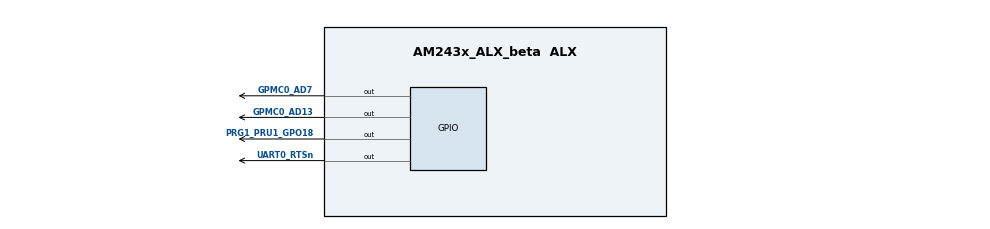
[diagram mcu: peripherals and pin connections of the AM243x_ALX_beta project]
/**
 * These arguments were used when this file was generated. They will be automatically applied on subsequent loads
 * via the GUI or CLI. Run CLI with '--help' for additional information on how to override these arguments.
 * @cliArgs --device "AM243x_ALX_beta" --package "ALX" --part "ALX" --context "r5fss0-0" --product "MCU_PLUS_SDK@07.03.01" --product "MCU_PLUS_IND_COMMS_LIBS@01.00.00.00"
 * @versions {"tool":"1.14.0+2667"}
 */

/**
 * Import the modules used in this configuration.
 */
const eeprom     = scripting.addModule("/board/eeprom/eeprom", {}, false);
const eeprom1    = eeprom.addInstance();
const flash      = scripting.addModule("/board/flash/flash", {}, false);
const flash1     = flash.addInstance();
const led        = scripting.addModule("/board/led/led", {}, false);
const led1       = led.addInstance();
const led2       = led.addInstance();
const led3       = led.addInstance();
const gpio       = scripting.addModule("/drivers/gpio/gpio", {}, false);
const gpio1      = gpio.addInstance();
const gpio2      = gpio.addInstance();
const gpio3      = gpio.addInstance();
const gpio4      = gpio.addInstance();
const i2c        = scripting.addModule("/drivers/i2c/i2c", {}, false);
const i2c1       = i2c.addInstance();
const pruicss    = scripting.addModule("/drivers/pruicss/pruicss", {}, false);
const pruicss1   = pruicss.addInstance();
const uart       = scripting.addModule("/drivers/uart/uart", {}, false);
const uart1      = uart.addInstance();
const ethercat   = scripting.addModule("/industrial_comms/ethercat/ethercat", {}, false);
const ethercat1  = ethercat.addInstance();
const clock      = scripting.addModule("/kernel/dpl/clock");
const debug_log  = scripting.addModule("/kernel/dpl/debug_log");
const mpu_armv7  = scripting.addModule("/kernel/dpl/mpu_armv7", {}, false);
const mpu_armv71 = mpu_armv7.addInstance();
const mpu_armv72 = mpu_armv7.addInstance();
const mpu_armv73 = mpu_armv7.addInstance();
const mpu_armv74 = mpu_armv7.addInstance();
const timer      = scripting.addModule("/kernel/dpl/timer", {}, false);
const timer1     = timer.addInstance();

/**
 * Write custom configuration values to the imported modules.
 */
eeprom1.$name = "CONFIG_EEPROM0";

flash1.$name                         = "CONFIG_FLASH0";
flash1.peripheralDriver.$name        = "CONFIG_OSPI0";
flash1.peripheralDriver.inputClkFreq = 200000000;

led1.$name = "CONFIG_LED0";
led1.name  = "TPIC2810";

led2.$name = "CONFIG_LED_STATUS";

led3.$name = "CONFIG_LED_ERROR";

led2.peripheralDriver      = gpio1;
gpio1.$name                = "CONFIG_GPIO_LED_STATUS";
gpio1.pinDir               = "OUTPUT";
gpio1.GPIO.gpioPin.rx      = false;
gpio1.GPIO.gpioPin.$assign = "GPMC0_AD7";

led3.peripheralDriver      = gpio2;
gpio2.$name                = "CONFIG_GPIO_LED_ERROR";
gpio2.pinDir               = "OUTPUT";
gpio2.GPIO.gpioPin.rx      = false;
gpio2.GPIO.gpioPin.$assign = "UART0_RTSn";

gpio3.$name                = "CONFIG_GPIO0_PHYRESET0";
gpio3.pinDir               = "OUTPUT";
gpio3.GPIO.gpioPin.$assign = "GPMC0_AD13";

gpio4.$name                = "CONFIG_GPIO0_PHYRESET1";
gpio4.pinDir               = "OUTPUT";
gpio4.GPIO.gpioPin.rx      = false;
gpio4.GPIO.gpioPin.$assign = "PRG1_PRU1_GPO18";

i2c1.$name            = "CONFIG_I2C0";
led1.peripheralDriver = i2c1;
i2c1.I2C.$assign      = "I2C0";

const i2c2               = i2c.addInstance({}, false);
i2c2.$name               = "CONFIG_I2C1";
eeprom1.peripheralDriver = i2c2;

uart1.$name = "CONFIG_UART_CONSOLE";

ethercat1.$name                                   = "CONFIG_ETHERCAT0";
ethercat1.instance                                = "ICSSG1";
ethercat1.ethphy[0].$name                         = "CONFIG_ETHPHY0";
ethercat1.ethphy[0].mdioPort                      = 3;
ethercat1.ethphy[1].$name                         = "CONFIG_ETHPHY1";
ethercat1.PRU_ICSSG1_MII_G_RT.MII1_RXLINK.$assign = "PRG1_PRU1_GPO8";

ethercat1.icss                           = pruicss1;
pruicss1.$name                           = "CONFIG_PRU_ICSS1";
pruicss1.AdditionalICSSSettings[0].$name = "CONFIG_PRU_ICSS_IO0";

debug_log.enableLogZoneInfo = true;

mpu_armv71.$name        = "CONFIG_MPU_REGION0";
mpu_armv71.size         = 31;
mpu_armv71.attributes   = "Device";
mpu_armv71.allowExecute = false;

mpu_armv72.$name             = "CONFIG_MPU_REGION1";
mpu_armv72.size              = 15;
mpu_armv72.accessPermissions = "Supervisor RD+WR, User RD";

mpu_armv73.$name             = "CONFIG_MPU_REGION2";
mpu_armv73.baseAddr          = 0x41010000;
mpu_armv73.size              = 15;
mpu_armv73.accessPermissions = "Supervisor RD+WR, User RD";

mpu_armv74.$name             = "CONFIG_MPU_REGION3";
mpu_armv74.baseAddr          = 0x70000000;
mpu_armv74.size              = 21;
mpu_armv74.accessPermissions = "Supervisor RD+WR, User RD";

timer1.$name         = "CONFIG_TIMER0";
timer1.startTimer    = true;
timer1.usecPerTick   = 100;
timer1.timerCallback = "OSAL_FREERTOS_callbackTimer";
timer1.TIMER.$assign = "DMTIMER4";

/**
 * Pinmux solution for unlocked pins/peripherals. This ensures that minor changes to the automatic solver in a future
 * version of the tool will not impact the pinmux you originally saw.  These lines can be completely deleted in order to
 * re-solve from scratch.
 */
flash1.peripheralDriver.OSPI.$suggestSolution                = "OSPI0";
flash1.peripheralDriver.OSPI.CLK.$suggestSolution            = "OSPI0_CLK";
flash1.peripheralDriver.OSPI.CSn0.$suggestSolution           = "OSPI0_CSn0";
flash1.peripheralDriver.OSPI.D3.$suggestSolution             = "OSPI0_D3";
flash1.peripheralDriver.OSPI.D2.$suggestSolution             = "OSPI0_D2";
flash1.peripheralDriver.OSPI.D1.$suggestSolution             = "OSPI0_D1";
flash1.peripheralDriver.OSPI.D0.$suggestSolution             = "OSPI0_D0";
gpio1.GPIO.$suggestSolution                                  = "GPIO0";
gpio2.GPIO.$suggestSolution                                  = "GPIO1";
gpio3.GPIO.$suggestSolution                                  = "GPIO0";
gpio4.GPIO.$suggestSolution                                  = "GPIO0";
i2c1.I2C.SCL.$suggestSolution                                = "I2C0_SCL";
i2c1.I2C.SDA.$suggestSolution                                = "I2C0_SDA";
i2c2.I2C.$suggestSolution                                    = "I2C1";
i2c2.I2C.SCL.$suggestSolution                                = "I2C1_SCL";
i2c2.I2C.SDA.$suggestSolution                                = "I2C1_SDA";
uart1.UART.$suggestSolution                                  = "USART0";
uart1.UART.RXD.$suggestSolution                              = "UART0_RXD";
uart1.UART.TXD.$suggestSolution                              = "UART0_TXD";
ethercat1.PRU_ICSSG1_MDIO.$suggestSolution                   = "PRU_ICSSG1_MDIO0";
ethercat1.PRU_ICSSG1_MDIO.MDC.$suggestSolution               = "PRG1_MDIO0_MDC";
ethercat1.PRU_ICSSG1_MDIO.MDIO.$suggestSolution              = "PRG1_MDIO0_MDIO";
ethercat1.PRU_ICSSG1_IEP.$suggestSolution                    = "PRU_ICSSG1_IEP0";
ethercat1.PRU_ICSSG1_IEP.EDC_LATCH_IN0.$suggestSolution      = "PRG1_PRU0_GPO18";
ethercat1.PRU_ICSSG1_IEP.EDC_LATCH_IN1.$suggestSolution      = "PRG1_PRU0_GPO7";
ethercat1.PRU_ICSSG1_IEP.EDC_SYNC_OUT0.$suggestSolution      = "PRG1_PRU0_GPO19";
ethercat1.PRU_ICSSG1_IEP.EDC_SYNC_OUT1.$suggestSolution      = "PRG1_PRU0_GPO17";
ethercat1.PRU_ICSSG1_IEP.EDIO_DATA_IN_OUT28.$suggestSolution = "PRG1_PRU0_GPO9";
ethercat1.PRU_ICSSG1_IEP.EDIO_DATA_IN_OUT29.$suggestSolution = "PRG1_PRU0_GPO10";
ethercat1.PRU_ICSSG1_IEP.EDIO_DATA_IN_OUT30.$suggestSolution = "PRG1_PRU1_GPO9";
ethercat1.PRU_ICSSG1_IEP.EDIO_DATA_IN_OUT31.$suggestSolution = "PRG1_PRU1_GPO10";
ethercat1.PRU_ICSSG1_MII_G_RT.$suggestSolution               = "PRU_ICSSG1_MII_G_RT";
ethercat1.PRU_ICSSG1_MII_G_RT.MII0_RXD0.$suggestSolution     = "PRG1_PRU0_GPO0";
ethercat1.PRU_ICSSG1_MII_G_RT.MII0_RXD1.$suggestSolution     = "PRG1_PRU0_GPO1";
ethercat1.PRU_ICSSG1_MII_G_RT.MII0_RXD2.$suggestSolution     = "PRG1_PRU0_GPO2";
ethercat1.PRU_ICSSG1_MII_G_RT.MII0_RXD3.$suggestSolution     = "PRG1_PRU0_GPO3";
ethercat1.PRU_ICSSG1_MII_G_RT.MII0_RXDV.$suggestSolution     = "PRG1_PRU0_GPO4";
ethercat1.PRU_ICSSG1_MII_G_RT.MII0_RXER.$suggestSolution     = "PRG1_PRU0_GPO5";
ethercat1.PRU_ICSSG1_MII_G_RT.MII0_RXLINK.$suggestSolution   = "PRG1_PRU0_GPO8";
ethercat1.PRU_ICSSG1_MII_G_RT.MII0_TXD0.$suggestSolution     = "PRG1_PRU0_GPO11";
ethercat1.PRU_ICSSG1_MII_G_RT.MII0_TXD1.$suggestSolution     = "PRG1_PRU0_GPO12";
ethercat1.PRU_ICSSG1_MII_G_RT.MII0_TXD2.$suggestSolution     = "PRG1_PRU0_GPO13";
ethercat1.PRU_ICSSG1_MII_G_RT.MII0_TXD3.$suggestSolution     = "PRG1_PRU0_GPO14";
ethercat1.PRU_ICSSG1_MII_G_RT.MII0_TXEN.$suggestSolution     = "PRG1_PRU0_GPO15";
ethercat1.PRU_ICSSG1_MII_G_RT.MII1_RXD0.$suggestSolution     = "PRG1_PRU1_GPO0";
ethercat1.PRU_ICSSG1_MII_G_RT.MII1_RXD1.$suggestSolution     = "PRG1_PRU1_GPO1";
ethercat1.PRU_ICSSG1_MII_G_RT.MII1_RXD2.$suggestSolution     = "PRG1_PRU1_GPO2";
ethercat1.PRU_ICSSG1_MII_G_RT.MII1_RXD3.$suggestSolution     = "PRG1_PRU1_GPO3";
ethercat1.PRU_ICSSG1_MII_G_RT.MII1_RXDV.$suggestSolution     = "PRG1_PRU1_GPO4";
ethercat1.PRU_ICSSG1_MII_G_RT.MII1_RXER.$suggestSolution     = "PRG1_PRU1_GPO5";
ethercat1.PRU_ICSSG1_MII_G_RT.MII1_TXD0.$suggestSolution     = "PRG1_PRU1_GPO11";
ethercat1.PRU_ICSSG1_MII_G_RT.MII1_TXD1.$suggestSolution     = "PRG1_PRU1_GPO12";
ethercat1.PRU_ICSSG1_MII_G_RT.MII1_TXD2.$suggestSolution     = "PRG1_PRU1_GPO13";
ethercat1.PRU_ICSSG1_MII_G_RT.MII1_TXD3.$suggestSolution     = "PRG1_PRU1_GPO14";
ethercat1.PRU_ICSSG1_MII_G_RT.MII1_TXEN.$suggestSolution     = "PRG1_PRU1_GPO15";
ethercat1.PRU_ICSSG1_MII_G_RT.MII_MR0_CLK.$suggestSolution   = "PRG1_PRU0_GPO6";
ethercat1.PRU_ICSSG1_MII_G_RT.MII_MR1_CLK.$suggestSolution   = "PRG1_PRU1_GPO6";
ethercat1.PRU_ICSSG1_MII_G_RT.MII_MT0_CLK.$suggestSolution   = "PRG1_PRU0_GPO16";
ethercat1.PRU_ICSSG1_MII_G_RT.MII_MT1_CLK.$suggestSolution   = "PRG1_PRU1_GPO16";
